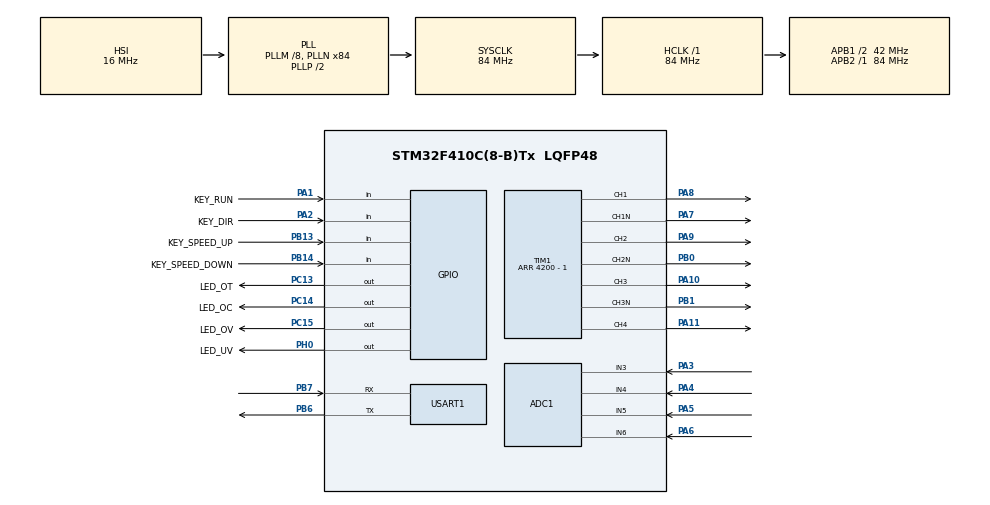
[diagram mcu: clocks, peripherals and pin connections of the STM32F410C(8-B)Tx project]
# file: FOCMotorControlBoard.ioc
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ADC1.Channel-0\#ChannelRegularConversion=ADC_CHANNEL_3
ADC1.Channel-4\#ChannelInjectedConversion=ADC_CHANNEL_3
ADC1.Channel-5\#ChannelInjectedConversion=ADC_CHANNEL_4
ADC1.Channel-6\#ChannelInjectedConversion=ADC_CHANNEL_5
ADC1.Channel-7\#ChannelInjectedConversion=ADC_CHANNEL_6
ADC1.ExternalTrigInjecConv=ADC_EXTERNALTRIGINJECCONV_T1_CC4
ADC1.InjNumberOfConversion=4
ADC1.InjectedOffset-4\#ChannelInjectedConversion=0
ADC1.InjectedOffset-5\#ChannelInjectedConversion=0
ADC1.InjectedOffset-6\#ChannelInjectedConversion=0
ADC1.InjectedOffset-7\#ChannelInjectedConversion=0
ADC1.InjectedRank-4\#ChannelInjectedConversion=1
ADC1.InjectedRank-5\#ChannelInjectedConversion=2
ADC1.InjectedRank-6\#ChannelInjectedConversion=3
ADC1.InjectedRank-7\#ChannelInjectedConversion=4
ADC1.NbrOfConversion=1
ADC1.NbrOfConversionFlag=1
ADC1.Rank-0\#ChannelRegularConversion=1
ADC1.SamplingTime-0\#ChannelRegularConversion=ADC_SAMPLETIME_15CYCLES
ADC1.SamplingTime-4\#ChannelInjectedConversion=ADC_SAMPLETIME_3CYCLES
ADC1.SamplingTime-5\#ChannelInjectedConversion=ADC_SAMPLETIME_3CYCLES
ADC1.SamplingTime-6\#ChannelInjectedConversion=ADC_SAMPLETIME_3CYCLES
ADC1.SamplingTime-7\#ChannelInjectedConversion=ADC_SAMPLETIME_3CYCLES
ADC1.ScanConvMode=ENABLE
ADC1.master=1
Dma.Request0=USART1_RX
Dma.Request1=USART1_TX
Dma.USART1_RX.0.Direction=DMA_PERIPH_TO_MEMORY
Dma.USART1_RX.0.FIFOMode=DMA_FIFOMODE_DISABLE
Dma.USART1_RX.0.Instance=DMA2_Stream2
Dma.USART1_RX.0.MemDataAlignment=DMA_MDATAALIGN_BYTE
Dma.USART1_RX.0.MemInc=DMA_MINC_ENABLE
Dma.USART1_RX.0.Mode=DMA_NORMAL
Dma.USART1_RX.0.PeriphDataAlignment=DMA_PDATAALIGN_BYTE
Dma.USART1_RX.0.PeriphInc=DMA_PINC_DISABLE
Dma.USART1_RX.0.Priority=DMA_PRIORITY_LOW
Dma.USART1_TX.1.Direction=DMA_MEMORY_TO_PERIPH
Dma.USART1_TX.1.FIFOMode=DMA_FIFOMODE_DISABLE
Dma.USART1_TX.1.Instance=DMA2_Stream7
Dma.USART1_TX.1.MemDataAlignment=DMA_MDATAALIGN_BYTE
Dma.USART1_TX.1.MemInc=DMA_MINC_ENABLE
Dma.USART1_TX.1.Mode=DMA_NORMAL
Dma.USART1_TX.1.PeriphDataAlignment=DMA_PDATAALIGN_BYTE
Dma.USART1_TX.1.PeriphInc=DMA_PINC_DISABLE
Dma.USART1_TX.1.Priority=DMA_PRIORITY_LOW
Mcu.Family=STM32F4
Mcu.Name=STM32F410C(8-B)Tx
Mcu.Package=LQFP48
NVIC.ADC_IRQn=true\:0\:0\:false\:false\:true\:true\:true\:true
NVIC.DMA2_Stream2_IRQn=true\:0\:0\:false\:false\:true\:false\:true\:true
NVIC.DMA2_Stream7_IRQn=true\:0\:0\:false\:false\:true\:false\:true\:true
NVIC.PriorityGroup=NVIC_PRIORITYGROUP_4
NVIC.TIM1_BRK_TIM9_IRQn=true\:0\:0\:false\:false\:true\:true\:true\:true
NVIC.USART1_IRQn=true\:0\:0\:false\:false\:true\:false\:true\:true
PA1.GPIO_Label=KEY_RUN
PA1.GPIO_PuPd=GPIO_PULLUP
PA1.Signal=GPIO_Input
PA10.Signal=S_TIM1_CH3
PA11.Signal=S_TIM1_CH4
PA13.Mode=Serial_Wire
PA13.Signal=SYS_JTMS-SWDIO
PA14.Mode=Serial_Wire
PA14.Signal=SYS_JTCK-SWCLK
PA2.GPIO_Label=KEY_DIR
PA2.GPIO_PuPd=GPIO_PULLUP
PA2.Signal=GPIO_Input
PA3.Signal=ADCx_IN3
PA4.Signal=ADCx_IN4
PA5.Signal=ADCx_IN5
PA6.Signal=ADCx_IN6
PA7.Mode=PWM Generation1 CH1 CH1N
PA7.Signal=TIM1_CH1N
PA8.Signal=S_TIM1_CH1
PA9.Signal=S_TIM1_CH2
PB0.Mode=PWM Generation2 CH2 CH2N
PB0.Signal=TIM1_CH2N
PB1.Mode=PWM Generation3 CH3 CH3N
PB1.Signal=TIM1_CH3N
PB13.GPIO_Label=KEY_SPEED_UP
PB13.GPIO_PuPd=GPIO_PULLUP
PB13.Signal=GPIO_Input
PB14.GPIO_Label=KEY_SPEED_DOWN
PB14.GPIO_PuPd=GPIO_PULLUP
PB14.Signal=GPIO_Input
PB6.Mode=Asynchronous
PB6.Signal=USART1_TX
PB7.Mode=Asynchronous
PB7.Signal=USART1_RX
PC13-ANTI_TAMP.GPIO_Label=LED_OT
PC13-ANTI_TAMP.Signal=GPIO_Output
PC14-OSC32_IN.GPIO_Label=LED_OC
PC14-OSC32_IN.Signal=GPIO_Output
PC15-OSC32_OUT.GPIO_Label=LED_OV
PC15-OSC32_OUT.Signal=GPIO_Output
PH0\ -\ OSC_IN.GPIO_Label=LED_UV
PH0\ -\ OSC_IN.Signal=GPIO_Output
ProjectManager.HeapSize=0x200
ProjectManager.StackSize=0x400
ProjectManager.TargetToolchain=MDK-ARM V5.32
RCC.48MHZClocksFreq_Value=42000000
RCC.AHBFreq_Value=84000000
RCC.APB1CLKDivider=RCC_HCLK_DIV2
RCC.APB1Freq_Value=42000000
RCC.APB1TimFreq_Value=84000000
RCC.APB2Freq_Value=84000000
RCC.APB2TimFreq_Value=84000000
RCC.CortexFreq_Value=84000000
RCC.HCLKFreq_Value=84000000
RCC.HSE_VALUE=25000000
RCC.HSI_VALUE=16000000
RCC.LSE_VALUE=32768
RCC.PLLM=8
RCC.PLLN=84
RCC.SYSCLKFreq_VALUE=84000000
RCC.SYSCLKSource=RCC_SYSCLKSOURCE_PLLCLK
RCC.VCOOutputFreq_Value=168000000
SH.ADCx_IN3.0=ADC1_IN3,IN3
SH.ADCx_IN4.0=ADC1_IN4,IN4
SH.ADCx_IN5.0=ADC1_IN5,IN5
SH.ADCx_IN6.0=ADC1_IN6,IN6
SH.S_TIM1_CH1.0=TIM1_CH1,PWM Generation1 CH1 CH1N
SH.S_TIM1_CH2.0=TIM1_CH2,PWM Generation2 CH2 CH2N
SH.S_TIM1_CH3.0=TIM1_CH3,PWM Generation3 CH3 CH3N
SH.S_TIM1_CH4.0=TIM1_CH4,PWM Generation4 CH4
TIM1.Channel-PWM\ Generation1\ CH1\ CH1N=TIM_CHANNEL_1
TIM1.Channel-PWM\ Generation2\ CH2\ CH2N=TIM_CHANNEL_2
TIM1.Channel-PWM\ Generation3\ CH3\ CH3N=TIM_CHANNEL_3
TIM1.Channel-PWM\ Generation4\ CH4=TIM_CHANNEL_4
TIM1.CounterMode=TIM_COUNTERMODE_CENTERALIGNED1
TIM1.DeadTime=84
TIM1.OCMode_PWM-PWM\ Generation4\ CH4=TIM_OCMODE_PWM2
TIM1.OffStateIDLEMode=TIM_OSSI_ENABLE
TIM1.OffStateRunMode=TIM_OSSR_ENABLE
TIM1.Period=4200 - 1
TIM1.Pulse-PWM\ Generation1\ CH1\ CH1N=1
TIM1.Pulse-PWM\ Generation2\ CH2\ CH2N=1
TIM1.Pulse-PWM\ Generation4\ CH4=4200 - 2
TIM1.RepetitionCounter=1
TIM1.TIM_MasterOutputTrigger=TIM_TRGO_UPDATE
TIM5.Period=65535
USART1.VirtualMode=VM_ASYNC
VP_CRC_VS_CRC.Mode=CRC_Activate
VP_TIM1_VS_ClockSourceINT.Mode=Internal
VP_TIM5_VS_ClockSourceINT.Mode=Internal
board=custom

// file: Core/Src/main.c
/* USER CODE BEGIN Header */
/**
 ******************************************************************************
 * @file           : main.c
 * @brief          : Main program body
 ******************************************************************************
 * @attention
 *
 * Copyright (c) 2026 STMicroelectronics.
 * All rights reserved.
 *
 * This software is licensed under terms that can be found in the LICENSE file
 * in the root directory of this software component.
 * If no LICENSE file comes with this software, it is provided AS-IS.
 *
 ******************************************************************************
 */
/* USER CODE END Header */
#include "main.h"
#include "adc.h"
#include "crc.h"
#include "dma.h"
#include "tim.h"
#include "usart.h"
#include "gpio.h"

/* USER CODE BEGIN Includes */
#include "bsp.h"
#include <stdio.h>
/* USER CODE END Includes */

void SystemClock_Config(void);

int main(void)
{

  /* MCU Configuration--------------------------------------------------------*/

  /* Reset of all peripherals, Initializes the Flash interface and the Systick. */
  HAL_Init();

  /* Configure the system clock */
  SystemClock_Config();

  /* Initialize all configured peripherals */
  MX_GPIO_Init();
  MX_DMA_Init();
  MX_USART1_UART_Init();
  MX_ADC1_Init();
  MX_TIM1_Init();
  MX_CRC_Init();
  MX_TIM5_Init();
  /* USER CODE BEGIN 2 */
  /* 第二阶段开始，main.c 不再直接操作 ADC/PWM/按键。
   * 所有板级逻辑都交给 BSP 层，方便后面逐步恢复电机控制功能。
   */
  BspInit();
  /* USER CODE END 2 */

  /* Infinite loop */
  while (1)
  {

    /* USER CODE BEGIN 3 */
    /* BSP 主任务：
     * 1. 扫描按键和处理串口命令；
     * 2. 更新电机状态机；
     * 3. 定时打印调试信息。
     */
    BspTask();
  }
  /* USER CODE END 3 */
}

void SystemClock_Config(void)
{
  RCC_OscInitTypeDef RCC_OscInitStruct = {0};
  RCC_ClkInitTypeDef RCC_ClkInitStruct = {0};

  /** Configure the main internal regulator output voltage
  */
  __HAL_RCC_PWR_CLK_ENABLE();
  __HAL_PWR_VOLTAGESCALING_CONFIG(PWR_REGULATOR_VOLTAGE_SCALE1);

  /** Initializes the RCC Oscillators according to the specified parameters
  * in the RCC_OscInitTypeDef structure.
  */
  RCC_OscInitStruct.OscillatorType = RCC_OSCILLATORTYPE_HSI;
  RCC_OscInitStruct.HSIState = RCC_HSI_ON;
  RCC_OscInitStruct.HSICalibrationValue = RCC_HSICALIBRATION_DEFAULT;
  RCC_OscInitStruct.PLL.PLLState = RCC_PLL_ON;
  RCC_OscInitStruct.PLL.PLLSource = RCC_PLLSOURCE_HSI;
  RCC_OscInitStruct.PLL.PLLM = 8;
  RCC_OscInitStruct.PLL.PLLN = 84;
  RCC_OscInitStruct.PLL.PLLP = RCC_PLLP_DIV2;
  RCC_OscInitStruct.PLL.PLLQ = 4;
  RCC_OscInitStruct.PLL.PLLR = 2;
  if (HAL_RCC_OscConfig(&RCC_OscInitStruct) != HAL_OK)
  {
    Error_Handler();
  }

  /** Initializes the CPU, AHB and APB buses clocks
  */
  RCC_ClkInitStruct.ClockType = RCC_CLOCKTYPE_HCLK|RCC_CLOCKTYPE_SYSCLK
                              |RCC_CLOCKTYPE_PCLK1|RCC_CLOCKTYPE_PCLK2;
  RCC_ClkInitStruct.SYSCLKSource = RCC_SYSCLKSOURCE_PLLCLK;
  RCC_ClkInitStruct.AHBCLKDivider = RCC_SYSCLK_DIV1;
  RCC_ClkInitStruct.APB1CLKDivider = RCC_HCLK_DIV2;
  RCC_ClkInitStruct.APB2CLKDivider = RCC_HCLK_DIV1;

  if (HAL_RCC_ClockConfig(&RCC_ClkInitStruct, FLASH_LATENCY_2) != HAL_OK)
  {
    Error_Handler();
  }
}

void Error_Handler(void)
{
  __disable_irq();
  while (1)
  {
  }
}
